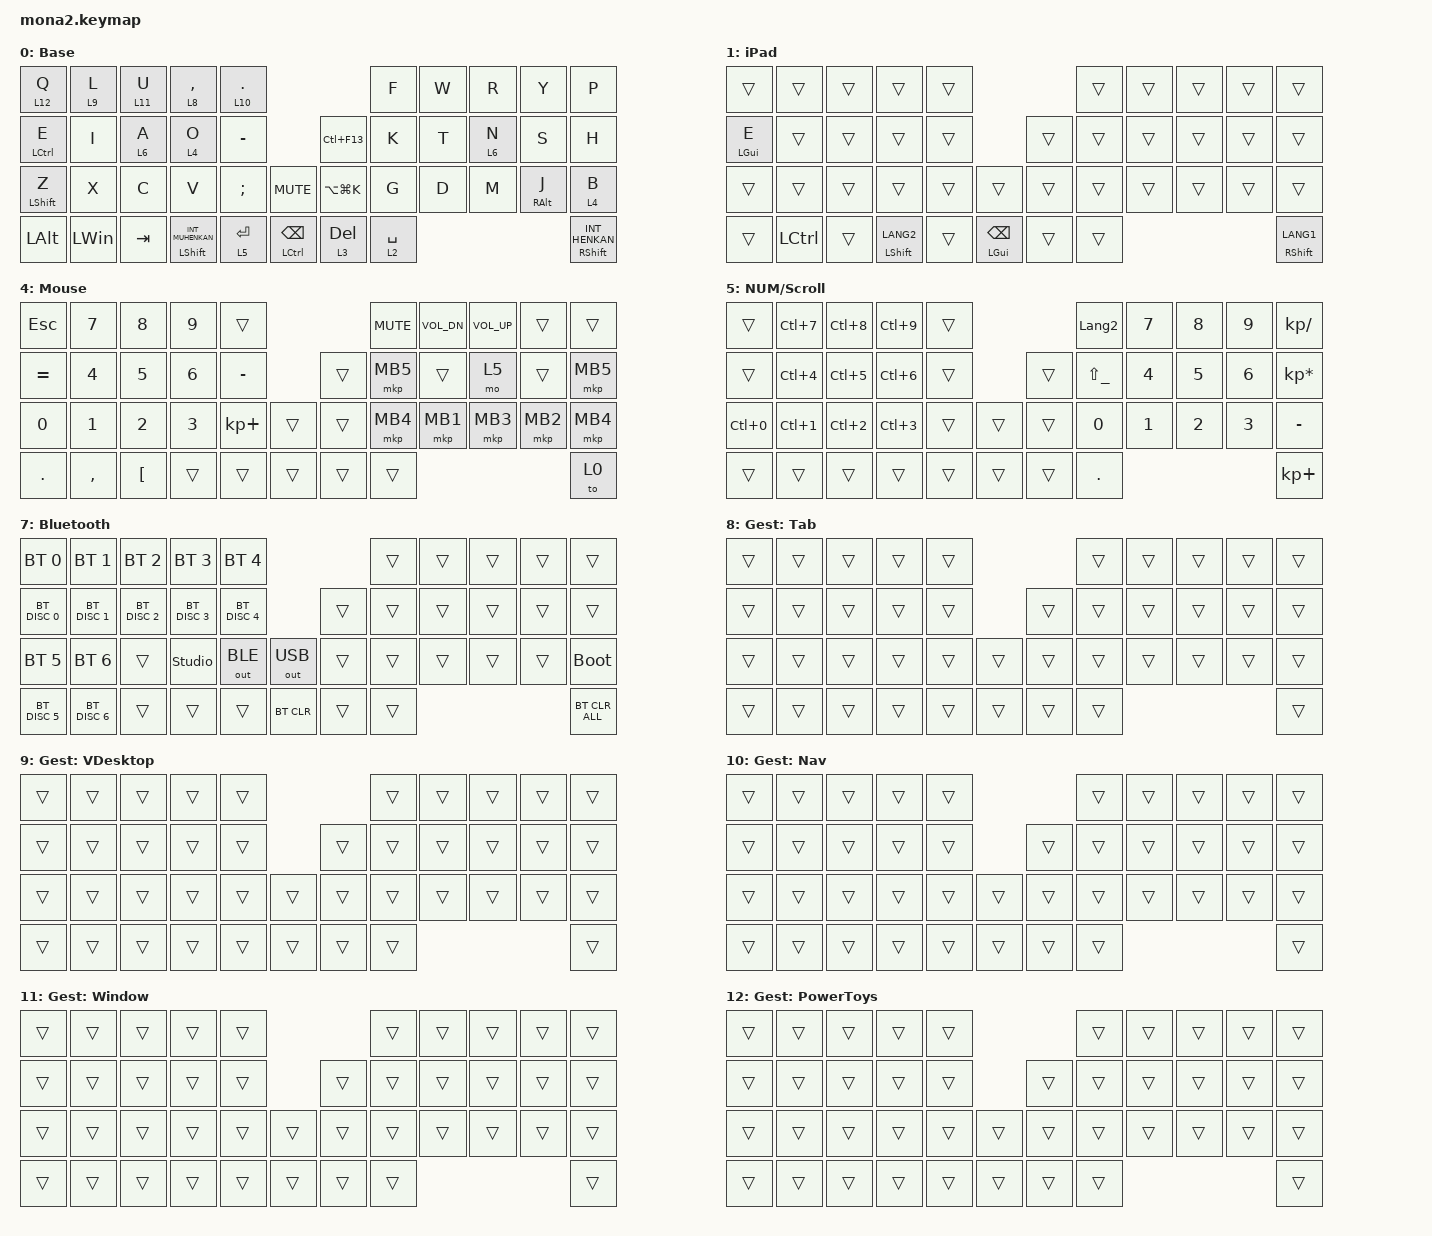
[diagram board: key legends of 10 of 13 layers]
#include <input/processors.dtsi>
#include <dt-bindings/zmk/input_transform.h>
#include <zephyr/dt-bindings/input/input-event-codes.h>
#include <behaviors.dtsi>
#include <dt-bindings/zmk/bt.h>
#include <dt-bindings/zmk/keys.h>
#include <dt-bindings/zmk/outputs.h>
/* pointing.h の #ifndef より前に置くこと。後ろに書くと、ヘッダが既定値 10 で
 * 定義した後の再定義になり "redefined" 警告が出る (展開は遅延なので値自体は
 * 100 で効く)。本家と同じく一旦 undef して定義し直す。 */
/* ── 1クリック = 1ノッチ になるように逆算した値 ──
 * この値はカウント数ではなく「速さ」。&msc (zmk,behavior-input-two-axis) は
 * 押している間 trigger_period_ms (既定 16ms) ごとに
 *     move = SCRL_VAL * trigger_period_ms / 1000
 * を出力する (behavior_input_two_axis.c の update_movement_1d)。
 * 1ティックあたり SCRL_VAL * 0.016 カウント、小数は切り捨て。
 *
 * さらに CONFIG_ZMK_POINTING_SMOOTH_SCROLLING=y だと HID の
 * Resolution Multiplier (hid.h: logical 0-15 / physical 1-16) をホストが
 * 最大 16 に設定するので、ホスト側で 1カウント = 1/16 ノッチになる。
 * ZMK 側で補正するはずの input_listener.c の apply_resolution_scaling は
 * scaled を計算したあと evt->value = val としていて割った結果を捨てている
 * (本家 main も同じ)。つまりファームは生値を送り、ホストだけが 16 で割る。
 *
 *   1000 * 0.016 = 16 カウント → 16/16 = 1ノッチ/クリック
 *
 * 200 のままだと 3カウント = 3/16 ノッチで、5〜6クリック回さないと 1行
 * 進まない。トラックボール側はこの値を通らないので
 * ここを上げても影響しない。エンコーダ出力には mscbase×msclyr が
 * 掛かるので、最終段数はそちらとの掛け算になる。 */
#undef ZMK_POINTING_DEFAULT_SCRL_VAL
#define ZMK_POINTING_DEFAULT_SCRL_VAL 1000
#include <dt-bindings/zmk/pointing.h>
/* ランタイムマクロの &rmacro <slot> を提供。スロット番号は Studio で
 * マクロを作成したときに割り当てられる。 */
#include <behaviors/runtime_macro.dtsi>
/* &mg_set N を提供。押している間だけ RPC 側のセットが有効になる。
 * ただし Studio からは割り当てられないので、下の mg_set_0/1/2 を使う。 */
#include <mouse-gesture-rpc.dtsi>
#include "gestures.dtsi"

/* DYA Studio 用の「セット番号固定」ジェスチャーキー。
 *
 * Studio はパラメータ付きのカスタム behavior を保持できないため、汎用の
 * &mg_set N は Studio の一覧から割り当てられない。モジュール側は対策として
 * パラメータ無しの compatible "zmk,behavior-mg-set-fixed" を用意しているが、
 * ノード自体は定義していない (README にも記載なし) ので自前で作る。
 *
 * セット番号はノード名の末尾1文字から決まる (behavior_mg_set.c の
 * binding_set_id())。よってノード名は必ず _0 / _1 / _2 で終わらせること。
 * 判定が '0'..'2' 固定なので3セットが上限。 */
/ {
    behaviors {
        mg_set_0: behavior_mg_set_0 {
            compatible = "zmk,behavior-mg-set-fixed";
            #binding-cells = <0>;
            display-name = "Mouse Gesture Key 0";
        };

        mg_set_1: behavior_mg_set_1 {
            compatible = "zmk,behavior-mg-set-fixed";
            #binding-cells = <0>;
            display-name = "Mouse Gesture Key 1";
        };

        mg_set_2: behavior_mg_set_2 {
            compatible = "zmk,behavior-mg-set-fixed";
            #binding-cells = <0>;
            display-name = "Mouse Gesture Key 2";
        };
    };
};

&mt {
    flavor = "tap-preferred";
    quick-tap-ms = <300>;
    require-prior-idle-ms = <125>;
    tapping-term-ms = <180>;
};

&lt {
    quick-tap-ms = <300>;
    flavor = "tap-preferred";
    require-prior-idle-ms = <125>;
    tapping-term-ms = <180>;
};

/* &msc (エンコーダのスクロール出力) の加速ランプを無効化。
 * 本家 (shakushakupanda) と同じ3行。
 * 無いと ZMK 既定 (time-to-max-speed-ms = 300) が効き、1クリックでは
 * 立ち上がりの端数しか出ない。0 にすると1クリック分の値が即出る。 */
&msc {
    delay-ms = <0>;
    time-to-max-speed-ms = <0>;
    acceleration-exponent = <0>;
};

/ {
    input_processors {
        /* エンコーダ (&msc) 用ランタイムスケーラ2段。Studioから倍率・対象レイヤーを
         * 変えられる。実効 = mscbase × msclyr。
         * labelは7文字以内にすること (NAME_MAX_LEN=8、NUL込みで8に収める)。
         * x/y-codesは両方必須・同要素数 (上流bindingの制約)。反転なし=現行と同符号。 */
        mscbase: mscbase {
            compatible = "zmk,input-processor-runtime";
            processor-label = "mscbase";
            #input-processor-cells = <0>;
            type = <INPUT_EV_REL>;
            x-codes = <INPUT_REL_HWHEEL>;
            y-codes = <INPUT_REL_WHEEL>;
            track-remainders;
            scale-multiplier = <1>;
            scale-divisor = <1>;
            active-layers = <0>; // 全レイヤー (0=全部)。ベース感度はここ
        };

        msclyr: msclyr {
            compatible = "zmk,input-processor-runtime";
            processor-label = "msclyr";
            #input-processor-cells = <0>;
            type = <INPUT_EV_REL>;
            x-codes = <INPUT_REL_HWHEEL>;
            y-codes = <INPUT_REL_WHEEL>;
            track-remainders;
            scale-multiplier = <3>;
            scale-divisor = <1>;
            // BIT(3)=SYM2のみ。旧speed_up(layers=<3>)+scaler 3 1と同等。
            // BIT()がkeymap側で使えるか不明なためリテラル8で書く。
            active-layers = <8>; // レイヤー別倍率はここ。対象はStudioのマスクで足せる
        };
    };

    combos {
        compatible = "zmk,combos";

        layer4_ESC {
            bindings = <&lt 8 ESC>;
            key-positions = <39 38>;
        };

        tab1 {
            bindings = <&kp TAB>;
            key-positions = <11 12>;
        };

        tab {
            bindings = <&kp TAB>;
            key-positions = <10 11>;
        };

        esc {
            bindings = <&kp ESCAPE>;
            key-positions = <0 1>;
        };

        caps {
            bindings = <&kp CAPSLOCK>;
            key-positions = <21 22>;
        };

        BS {
            bindings = <&kp BACKSPACE>;
            key-positions = <8 9>;
        };

        LANG_2 {
            bindings = <&kp LANGUAGE_2>;
            key-positions = <12 13>;
        };

        LANG_1 {
            bindings = <&kp LANGUAGE_1>;
            key-positions = <17 18>;
        };

        Layer_6 {
            bindings = <&mo 7>;
            key-positions = <29 30>;
        };

        Layer_4 {
            bindings = <&mo 5>;
            key-positions = <31 30>;
        };

        Soft-Off {
            bindings = <&soft_off>;
            key-positions = <17 18 12 13 37 40>;
        };

        ctrl_alt_tab {
            bindings = <&kp LA(LC(TAB))>;
            key-positions = <2 3>;
        };

        Ring_Menu {
            bindings = <&Left_Right_Click>;
            key-positions = <29 31>;
        };
    };

    macros {
        to_layer_0: to_layer_0 {
            compatible = "zmk,behavior-macro-one-param";
            #binding-cells = <1>;
            bindings = <&to 0 &macro_param_1to1 &kp MACRO_PLACEHOLDER>;
            label = "TO_LAYER_0";
        };

        BrowsToExploree: BrowsToExploree {
            compatible = "zmk,behavior-macro";
            #binding-cells = <0>;
            bindings = <&kp LS(LA(B)) &kp ENTER &kp LG(NUMBER_1)>;
            label = "BROWSTOEXPLOREE";
        };

        Left_Right_Click: Left_Right_Click {
            compatible = "zmk,behavior-macro";
            #binding-cells = <0>;
            label = "LEFT_RIGHT_CLICK";
            bindings =
                <&macro_press>,
                <&mkp LCLK &mkp RCLK>,
                <&macro_pause_for_release>,
                <&macro_release>,
                <&mkp LCLK &mkp RCLK>;
        };
    };

    behaviors {
        lt_to_layer_0: lt_to_layer_0 {
            compatible = "zmk,behavior-hold-tap";
            label = "LAYER_TAP_TO_0";
            bindings = <&mo>, <&to_layer_0>;

            #binding-cells = <2>;
            tapping-term-ms = <200>;
        };

        scroll_up_down: mouse_wheel_up_down {
            compatible = "zmk,behavior-runtime-sensor-rotate";
            #sensor-binding-cells = <0>;
            /* &msc は押下時には何も出さず trigger_period_ms (16ms) 後の
             * 最初のティックで初めて出力する。tap-ms を 16 にすると
             * 「ティック」と「離してキャンセル」が同時になり、クリックが
             * 丸ごと無視されることがある。24 なら必ず 1ティックだけ出る
             * (次のティックは 32ms なので 2回出ることもない)。 */
            tap-ms = <24>;
            cw-binding = <&msc SCRL_DOWN>;
            ccw-binding = <&msc SCRL_UP>;
        };

        scroll_right_left: mouse_wheel_right_left {
            compatible = "zmk,behavior-runtime-sensor-rotate";
            #sensor-binding-cells = <0>;
            /* &msc は押下時には何も出さず trigger_period_ms (16ms) 後の
             * 最初のティックで初めて出力する。tap-ms を 16 にすると
             * 「ティック」と「離してキャンセル」が同時になり、クリックが
             * 丸ごと無視されることがある。24 なら必ず 1ティックだけ出る
             * (次のティックは 32ms なので 2回出ることもない)。 */
            tap-ms = <24>;
            cw-binding = <&msc SCRL_LEFT>;
            ccw-binding = <&msc SCRL_RIGHT>;
        };

        rsr_vol: rsr_vol {
            compatible = "zmk,behavior-runtime-sensor-rotate";
            #sensor-binding-cells = <0>;
            tap-ms = <5>; // 音量調整用に短めに設定
            cw-binding = <&kp C_VOL_DN>;
            ccw-binding = <&kp C_VOL_UP>;
        };

        new_behavior: new_behavior {
            compatible = "zmk,behavior-runtime-sensor-rotate";
            #sensor-binding-cells = <0>;
            /* &msc は押下時には何も出さず trigger_period_ms (16ms) 後の
             * 最初のティックで初めて出力する。tap-ms を 16 にすると
             * 「ティック」と「離してキャンセル」が同時になり、クリックが
             * 丸ごと無視されることがある。24 なら必ず 1ティックだけ出る
             * (次のティックは 32ms なので 2回出ることもない)。 */
            tap-ms = <24>;
            cw-binding = <&msc SCRL_LEFT>;
            ccw-binding = <&msc SCRL_RIGHT>;
            label = "NEW_BEHAVIOR";
        };
    };

    keymap {
        compatible = "zmk,keymap";

        default_layer {
            display-name = "Base";
            bindings = <
&lt 12 Q          &lt 9 L       &lt 11 U  &lt 8 COMMA                  &lt 10 PERIOD                                             &kp F        &kp W  &kp R    &kp Y            &kp P
&mt LCTRL E       &kp I         &lt 6 A   &lt 4 O                      &kp MINUS                                    &kp LC(F13)  &kp K        &kp T  &lt 6 N  &kp S            &kp H
&mt LEFT_SHIFT Z  &kp X         &kp C     &kp V                        &kp SEMICOLON  &kp C_MUTE                 &kp LA(LG(K))  &kp G        &kp D  &kp M    &mt RIGHT_ALT J  &lt 4 B
&kp LALT          &kp LEFT_WIN  &kp TAB   &mt LEFT_SHIFT INT_MUHENKAN  &lt 5 ENTER    &mt LEFT_CONTROL BACKSPACE    &lt 3 DEL   &lt 2 SPACE                                   &mt RIGHT_SHIFT INT_HENKAN
            >;

            sensor-bindings = <&scroll_up_down>;
        };

        /* iPad / iOS 用ベースレイヤー。
         *
         * zmk-feature-default-layer が OS 判定に応じて常時 ON にする。
         * レイヤー0を落とさず上に重ねる作りなので、Windows との差分だけを書き、
         * 残りは &trans でレイヤー0に落とす。
         *
         * 置き場所は index 1 でなければいけない。ZMK は有効なレイヤーを
         * 高い index から見るので、末尾に置くと機能レイヤー (2..12) を
         * すべて上書きしてしまう (torabo-tsuki で踏んだ)。
         *
         * sensor-bindings は書かない。書かないレイヤーはエンコーダの探索で
         * 読み飛ばされ、レイヤー0の &scroll_up_down に落ちる。 */
        iPad {
            display-name = "iPad";
            bindings = <
&trans      &trans     &trans  &trans                &trans                                                  &trans  &trans  &trans  &trans  &trans
&mt LGUI E  &trans     &trans  &trans                &trans                          &trans                  &trans  &trans  &trans  &trans  &trans
&trans      &trans     &trans  &trans                &trans  &trans                  &trans                  &trans  &trans  &trans  &trans  &trans
&trans      &kp LCTRL  &trans  &mt LEFT_SHIFT LANG2  &trans  &mt LEFT_GUI BACKSPACE  &trans  &trans                                          &mt RIGHT_SHIFT LANG1
            >;
        };

        NUM,SYM1 {
            display-name = "NUM/SYM1";
            bindings = <
&kp NUMBER_1              &kp NUMBER_2              &kp NUMBER_3  &kp NUMBER_4               &kp NUMBER_5                                      &kp NUMBER_6   &kp NUMBER_7          &kp NUMBER_8       &kp NUMBER_9          &kp NUMBER_0
&kp EQUAL                 &kp LEFT_BRACKET          &kp SLASH     &kp MINUS                  &kp LS(INTERNATIONAL_1)                   &trans  &kp SEMICOLON  &kp SQT               &kp RIGHT_BRACKET  &kp BACKSLASH         &kp INT_YEN
&kp LS(LA(LC(NUMBER_2)))  &kp LS(LA(LC(NUMBER_6)))  &kp PSCRN     &kp LS(LG(S))              &kp LA(PSCRN)            &kp LG(LS(V))    &trans  &kp CAPSLOCK   &kp LS(LC(NUMBER_2))  &kp LS(LC(I))      &kp LS(LC(NUMBER_1))  &kp SCROLLLOCK
&trans                    &trans                    &trans        &mt LEFT_SHIFT LANGUAGE_1  &trans                   &trans           &trans  &trans                                                                        &to 4
            >;

            sensor-bindings = <&scroll_right_left>;
        };

        SYM2 {
            display-name = "SYM2";
            bindings = <
&kp LS(NUMBER_1)   &kp LS(NUMBER_2)    &kp LS(NUMBER_3)  &kp LS(NUMBER_4)           &kp LS(N5)                                        &kp LS(NUMBER_6)   &kp LS(N7)         &kp LS(N8)             &kp LS(N9)            &kp LS(N0)
&kp LS(EQUAL)      &kp LS(LEFT_BRACE)  &kp QUESTION      &kp LS(UNDERSCORE)         &kp LS(INTERNATIONAL_1)                   &trans  &kp LS(SEMICOLON)  &kp LS(SQT)        &kp LS(RIGHT_BRACKET)  &kp LS(BACKSLASH)     &kp LS(INT_YEN)
&kp LS(LA(MINUS))  &trans              &trans            &BrowsToExploree           &rmacro 0                      &kp LG(LA(U))    &trans  &kp LC(LG(LEFT))   &kp LC(LG(RIGHT))  &kp LA(LC(LG(D)))      &kp LA(LC(LG(LEFT)))  &kp LA(LC(LG(RIGHT)))
&trans             &trans              &trans            &mt LEFT_SHIFT LANGUAGE_2  &trans                   &trans           &trans  &trans                                                                             &kp LC(LG(F4))
            >;

            sensor-bindings = <&scroll_up_down>;
        };

        MOUSE {
            display-name = "Mouse";
            bindings = <
&kp ESCAPE  &kp N7        &kp N8            &kp N9        &trans                          &kp C_MUTE  &kp C_VOL_DN  &kp C_VOL_UP  &trans    &trans
&kp EQUAL   &kp NUMBER_4  &kp N5            &kp NUMBER_6  &kp MINUS            &trans  &mkp MB5    &trans        &mo 5         &trans    &mkp MB5
&kp N0      &kp NUMBER_1  &kp NUMBER_2      &kp NUMBER_3  &kp KP_PLUS   &trans    &trans  &mkp MB4    &mkp MB1      &mkp MB3      &mkp MB2  &mkp MB4
&kp DOT     &kp COMMA     &kp LEFT_BRACKET  &trans        &trans        &trans    &trans  &trans                                            &to 0
            >;

            sensor-bindings = <&rsr_vol>;
        };

        NUM-SCROLL {
            display-name = "NUM/Scroll";
            bindings = <
&trans      &kp LC(N7)        &kp LC(N8)        &kp LC(N9)        &trans                    &kp LANGUAGE_2      &kp N7  &kp N8  &kp N9  &kp KP_SLASH
&trans      &kp LC(NUMBER_4)  &kp LC(N5)        &kp LC(NUMBER_6)  &trans            &trans  &kp LS(UNDERSCORE)  &kp N4  &kp N5  &kp N6  &kp KP_ASTERISK
&kp LC(N0)  &kp LC(NUMBER_1)  &kp LC(NUMBER_2)  &kp LC(NUMBER_3)  &trans  &trans    &trans  &kp N0              &kp N1  &kp N2  &kp N3  &kp MINUS
&trans      &trans            &trans            &trans            &trans  &trans    &trans  &kp DOT                                     &kp KP_PLUS
            >;

            sensor-bindings = <&scroll_right_left>;
        };

        gest_arrow {
            display-name = "Gest: Arrow";
            bindings = <
&kp ESC  &kp F1  &kp F2   &kp F3   &kp F4                     &kp INS         &kp HOME  &kp UP    &kp END    &kp PG_UP
&trans   &kp F5  &kp F6   &kp F7   &kp F8             &trans  &kp LC(TAB)     &kp LEFT  &kp UP    &kp RIGHT  &kp PG_DN
&trans   &kp F9  &kp F10  &kp F11  &kp F12  &trans    &trans  &kp LS(LG(V))   &kp LEFT  &kp DOWN  &kp RIGHT  &kp LC(LA(LG(V)))
&trans   &trans  &trans   &trans   &trans   &trans    &trans  &kp INT_HENKAN                                 &trans
            >;

            sensor-bindings = <&scroll_right_left>;
        };

        bluetooth {
            display-name = "Bluetooth";
            bindings = <
&bt BT_SEL 0   &bt BT_SEL 1   &bt BT_SEL 2   &bt BT_SEL 3    &bt BT_SEL 4                           &trans  &trans  &trans  &trans  &trans
&bt BT_DISC 0  &bt BT_DISC 1  &bt BT_DISC 2  &bt BT_DISC 3   &bt BT_DISC 4                  &trans  &trans  &trans  &trans  &trans  &trans
&bt BT_SEL 5   &bt BT_SEL 6   &trans         &studio_unlock  &out OUT_BLE   &out OUT_USB    &trans  &trans  &trans  &trans  &trans  &bootloader
&bt BT_DISC 5  &bt BT_DISC 6  &trans         &trans          &trans         &bt BT_CLR      &trans  &trans                          &bt BT_CLR_ALL
            >;

            sensor-bindings = <&scroll_up_down>;
        };

        gest_tab {
            display-name = "Gest: Tab";
            bindings = <
&trans  &trans  &trans  &trans  &trans                    &trans  &trans  &trans  &trans  &trans
&trans  &trans  &trans  &trans  &trans            &trans  &trans  &trans  &trans  &trans  &trans
&trans  &trans  &trans  &trans  &trans  &trans    &trans  &trans  &trans  &trans  &trans  &trans
&trans  &trans  &trans  &trans  &trans  &trans    &trans  &trans                          &trans
            >;
        };

        gest_vdesktop {
            display-name = "Gest: VDesktop";
            bindings = <
&trans  &trans  &trans  &trans  &trans                    &trans  &trans  &trans  &trans  &trans
&trans  &trans  &trans  &trans  &trans            &trans  &trans  &trans  &trans  &trans  &trans
&trans  &trans  &trans  &trans  &trans  &trans    &trans  &trans  &trans  &trans  &trans  &trans
&trans  &trans  &trans  &trans  &trans  &trans    &trans  &trans                          &trans
            >;
        };

        gest_nav {
            display-name = "Gest: Nav";
            bindings = <
&trans  &trans  &trans  &trans  &trans                    &trans  &trans  &trans  &trans  &trans
&trans  &trans  &trans  &trans  &trans            &trans  &trans  &trans  &trans  &trans  &trans
&trans  &trans  &trans  &trans  &trans  &trans    &trans  &trans  &trans  &trans  &trans  &trans
&trans  &trans  &trans  &trans  &trans  &trans    &trans  &trans                          &trans
            >;
        };

        gest_window {
            display-name = "Gest: Window";
            bindings = <
&trans  &trans  &trans  &trans  &trans                    &trans  &trans  &trans  &trans  &trans
&trans  &trans  &trans  &trans  &trans            &trans  &trans  &trans  &trans  &trans  &trans
&trans  &trans  &trans  &trans  &trans  &trans    &trans  &trans  &trans  &trans  &trans  &trans
&trans  &trans  &trans  &trans  &trans  &trans    &trans  &trans                          &trans
            >;
        };

        gest_powertoys {
            display-name = "Gest: PowerToys";
            bindings = <
&trans  &trans  &trans  &trans  &trans                    &trans  &trans  &trans  &trans  &trans
&trans  &trans  &trans  &trans  &trans            &trans  &trans  &trans  &trans  &trans  &trans
&trans  &trans  &trans  &trans  &trans  &trans    &trans  &trans  &trans  &trans  &trans  &trans
&trans  &trans  &trans  &trans  &trans  &trans    &trans  &trans                          &trans
            >;
        };
    };
};

/* エンコーダ (&msc) 出力チェーン。倍率と対象レイヤーは上の
 * mscbase (ベース感度・全層) と msclyr (レイヤー別倍率) で持ち、
 * Studioから変えられる。旧speed_up(layers=<3>)+zip 3 1と同等が既定。
 * 2段ともactiveな層では乗算になるため、マスクは排他に保つこと。 */
&msc_input_listener {
    input-processors = <&mscbase &msclyr>;
};
